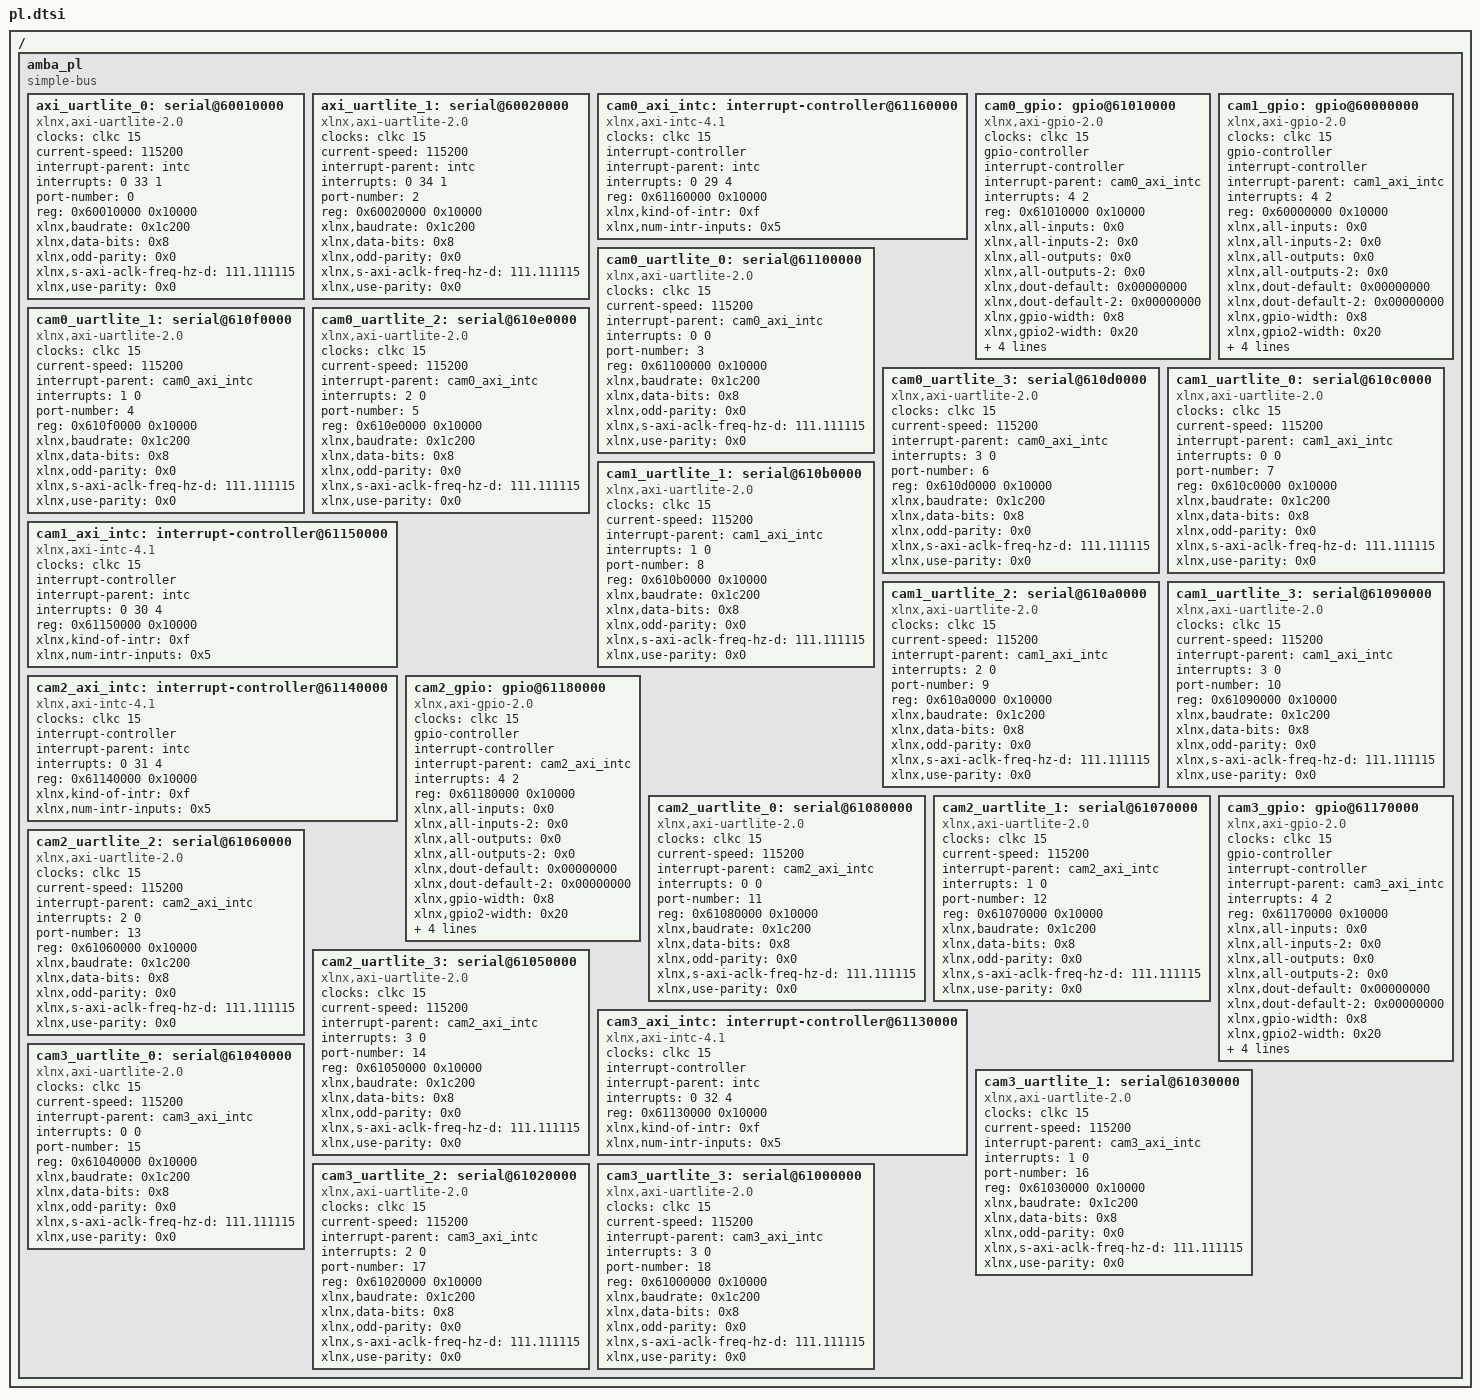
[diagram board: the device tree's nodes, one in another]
/*
 * CAUTION: This file is automatically generated by Xilinx.
 * Version:  
 * Today is: Thu Jul 18 16:22:56 2024
 */


/ {
	amba_pl: amba_pl {
		#address-cells = <1>;
		#size-cells = <1>;
		compatible = "simple-bus";
		ranges ;
		axi_uartlite_0: serial@60010000 {
			clock-names = "s_axi_aclk";
			clocks = <&clkc 15>;
			compatible = "xlnx,axi-uartlite-2.0", "xlnx,xps-uartlite-1.00.a";
			current-speed = <115200>;
			device_type = "serial";
			interrupt-names = "interrupt";
			interrupt-parent = <&intc>;
			interrupts = <0 33 1>;
			port-number = <0>;
			reg = <0x60010000 0x10000>;
			xlnx,baudrate = <0x1c200>;
			xlnx,data-bits = <0x8>;
			xlnx,odd-parity = <0x0>;
			xlnx,s-axi-aclk-freq-hz-d = "111.111115";
			xlnx,use-parity = <0x0>;
		};
		axi_uartlite_1: serial@60020000 {
			clock-names = "s_axi_aclk";
			clocks = <&clkc 15>;
			compatible = "xlnx,axi-uartlite-2.0", "xlnx,xps-uartlite-1.00.a";
			current-speed = <115200>;
			device_type = "serial";
			interrupt-names = "interrupt";
			interrupt-parent = <&intc>;
			interrupts = <0 34 1>;
			port-number = <2>;
			reg = <0x60020000 0x10000>;
			xlnx,baudrate = <0x1c200>;
			xlnx,data-bits = <0x8>;
			xlnx,odd-parity = <0x0>;
			xlnx,s-axi-aclk-freq-hz-d = "111.111115";
			xlnx,use-parity = <0x0>;
		};
		cam0_axi_intc: interrupt-controller@61160000 {
			#interrupt-cells = <2>;
			clock-names = "s_axi_aclk";
			clocks = <&clkc 15>;
			compatible = "xlnx,axi-intc-4.1", "xlnx,xps-intc-1.00.a";
			interrupt-controller ;
			interrupt-names = "irq";
			interrupt-parent = <&intc>;
			interrupts = <0 29 4>;
			reg = <0x61160000 0x10000>;
			xlnx,kind-of-intr = <0xf>;
			xlnx,num-intr-inputs = <0x5>;
		};
		cam0_gpio: gpio@61010000 {
			#gpio-cells = <2>;
			#interrupt-cells = <2>;
			clock-names = "s_axi_aclk";
			clocks = <&clkc 15>;
			compatible = "xlnx,axi-gpio-2.0", "xlnx,xps-gpio-1.00.a";
			gpio-controller ;
			interrupt-controller ;
			interrupt-names = "ip2intc_irpt";
			interrupt-parent = <&cam0_axi_intc>;
			interrupts = <4 2>;
			reg = <0x61010000 0x10000>;
			xlnx,all-inputs = <0x0>;
			xlnx,all-inputs-2 = <0x0>;
			xlnx,all-outputs = <0x0>;
			xlnx,all-outputs-2 = <0x0>;
			xlnx,dout-default = <0x00000000>;
			xlnx,dout-default-2 = <0x00000000>;
			xlnx,gpio-width = <0x8>;
			xlnx,gpio2-width = <0x20>;
			xlnx,interrupt-present = <0x1>;
			xlnx,is-dual = <0x0>;
			xlnx,tri-default = <0xFFFFFFFF>;
			xlnx,tri-default-2 = <0xFFFFFFFF>;
		};
		cam0_uartlite_0: serial@61100000 {
			clock-names = "s_axi_aclk";
			clocks = <&clkc 15>;
			compatible = "xlnx,axi-uartlite-2.0", "xlnx,xps-uartlite-1.00.a";
			current-speed = <115200>;
			device_type = "serial";
			interrupt-names = "interrupt";
			interrupt-parent = <&cam0_axi_intc>;
			interrupts = <0 0>;
			port-number = <3>;
			reg = <0x61100000 0x10000>;
			xlnx,baudrate = <0x1c200>;
			xlnx,data-bits = <0x8>;
			xlnx,odd-parity = <0x0>;
			xlnx,s-axi-aclk-freq-hz-d = "111.111115";
			xlnx,use-parity = <0x0>;
		};
		cam0_uartlite_1: serial@610f0000 {
			clock-names = "s_axi_aclk";
			clocks = <&clkc 15>;
			compatible = "xlnx,axi-uartlite-2.0", "xlnx,xps-uartlite-1.00.a";
			current-speed = <115200>;
			device_type = "serial";
			interrupt-names = "interrupt";
			interrupt-parent = <&cam0_axi_intc>;
			interrupts = <1 0>;
			port-number = <4>;
			reg = <0x610f0000 0x10000>;
			xlnx,baudrate = <0x1c200>;
			xlnx,data-bits = <0x8>;
			xlnx,odd-parity = <0x0>;
			xlnx,s-axi-aclk-freq-hz-d = "111.111115";
			xlnx,use-parity = <0x0>;
		};
		cam0_uartlite_2: serial@610e0000 {
			clock-names = "s_axi_aclk";
			clocks = <&clkc 15>;
			compatible = "xlnx,axi-uartlite-2.0", "xlnx,xps-uartlite-1.00.a";
			current-speed = <115200>;
			device_type = "serial";
			interrupt-names = "interrupt";
			interrupt-parent = <&cam0_axi_intc>;
			interrupts = <2 0>;
			port-number = <5>;
			reg = <0x610e0000 0x10000>;
			xlnx,baudrate = <0x1c200>;
			xlnx,data-bits = <0x8>;
			xlnx,odd-parity = <0x0>;
			xlnx,s-axi-aclk-freq-hz-d = "111.111115";
			xlnx,use-parity = <0x0>;
		};
		cam0_uartlite_3: serial@610d0000 {
			clock-names = "s_axi_aclk";
			clocks = <&clkc 15>;
			compatible = "xlnx,axi-uartlite-2.0", "xlnx,xps-uartlite-1.00.a";
			current-speed = <115200>;
			device_type = "serial";
			interrupt-names = "interrupt";
			interrupt-parent = <&cam0_axi_intc>;
			interrupts = <3 0>;
			port-number = <6>;
			reg = <0x610d0000 0x10000>;
			xlnx,baudrate = <0x1c200>;
			xlnx,data-bits = <0x8>;
			xlnx,odd-parity = <0x0>;
			xlnx,s-axi-aclk-freq-hz-d = "111.111115";
			xlnx,use-parity = <0x0>;
		};
		cam1_axi_intc: interrupt-controller@61150000 {
			#interrupt-cells = <2>;
			clock-names = "s_axi_aclk";
			clocks = <&clkc 15>;
			compatible = "xlnx,axi-intc-4.1", "xlnx,xps-intc-1.00.a";
			interrupt-controller ;
			interrupt-names = "irq";
			interrupt-parent = <&intc>;
			interrupts = <0 30 4>;
			reg = <0x61150000 0x10000>;
			xlnx,kind-of-intr = <0xf>;
			xlnx,num-intr-inputs = <0x5>;
		};
		cam1_gpio: gpio@60000000 {
			#gpio-cells = <2>;
			#interrupt-cells = <2>;
			clock-names = "s_axi_aclk";
			clocks = <&clkc 15>;
			compatible = "xlnx,axi-gpio-2.0", "xlnx,xps-gpio-1.00.a";
			gpio-controller ;
			interrupt-controller ;
			interrupt-names = "ip2intc_irpt";
			interrupt-parent = <&cam1_axi_intc>;
			interrupts = <4 2>;
			reg = <0x60000000 0x10000>;
			xlnx,all-inputs = <0x0>;
			xlnx,all-inputs-2 = <0x0>;
			xlnx,all-outputs = <0x0>;
			xlnx,all-outputs-2 = <0x0>;
			xlnx,dout-default = <0x00000000>;
			xlnx,dout-default-2 = <0x00000000>;
			xlnx,gpio-width = <0x8>;
			xlnx,gpio2-width = <0x20>;
			xlnx,interrupt-present = <0x1>;
			xlnx,is-dual = <0x0>;
			xlnx,tri-default = <0xFFFFFFFF>;
			xlnx,tri-default-2 = <0xFFFFFFFF>;
		};
		cam1_uartlite_0: serial@610c0000 {
			clock-names = "s_axi_aclk";
			clocks = <&clkc 15>;
			compatible = "xlnx,axi-uartlite-2.0", "xlnx,xps-uartlite-1.00.a";
			current-speed = <115200>;
			device_type = "serial";
			interrupt-names = "interrupt";
			interrupt-parent = <&cam1_axi_intc>;
			interrupts = <0 0>;
			port-number = <7>;
			reg = <0x610c0000 0x10000>;
			xlnx,baudrate = <0x1c200>;
			xlnx,data-bits = <0x8>;
			xlnx,odd-parity = <0x0>;
			xlnx,s-axi-aclk-freq-hz-d = "111.111115";
			xlnx,use-parity = <0x0>;
		};
		cam1_uartlite_1: serial@610b0000 {
			clock-names = "s_axi_aclk";
			clocks = <&clkc 15>;
			compatible = "xlnx,axi-uartlite-2.0", "xlnx,xps-uartlite-1.00.a";
			current-speed = <115200>;
			device_type = "serial";
			interrupt-names = "interrupt";
			interrupt-parent = <&cam1_axi_intc>;
			interrupts = <1 0>;
			port-number = <8>;
			reg = <0x610b0000 0x10000>;
			xlnx,baudrate = <0x1c200>;
			xlnx,data-bits = <0x8>;
			xlnx,odd-parity = <0x0>;
			xlnx,s-axi-aclk-freq-hz-d = "111.111115";
			xlnx,use-parity = <0x0>;
		};
		cam1_uartlite_2: serial@610a0000 {
			clock-names = "s_axi_aclk";
			clocks = <&clkc 15>;
			compatible = "xlnx,axi-uartlite-2.0", "xlnx,xps-uartlite-1.00.a";
			current-speed = <115200>;
			device_type = "serial";
			interrupt-names = "interrupt";
			interrupt-parent = <&cam1_axi_intc>;
			interrupts = <2 0>;
			port-number = <9>;
			reg = <0x610a0000 0x10000>;
			xlnx,baudrate = <0x1c200>;
			xlnx,data-bits = <0x8>;
			xlnx,odd-parity = <0x0>;
			xlnx,s-axi-aclk-freq-hz-d = "111.111115";
			xlnx,use-parity = <0x0>;
		};
		cam1_uartlite_3: serial@61090000 {
			clock-names = "s_axi_aclk";
			clocks = <&clkc 15>;
			compatible = "xlnx,axi-uartlite-2.0", "xlnx,xps-uartlite-1.00.a";
			current-speed = <115200>;
			device_type = "serial";
			interrupt-names = "interrupt";
			interrupt-parent = <&cam1_axi_intc>;
			interrupts = <3 0>;
			port-number = <10>;
			reg = <0x61090000 0x10000>;
			xlnx,baudrate = <0x1c200>;
			xlnx,data-bits = <0x8>;
			xlnx,odd-parity = <0x0>;
			xlnx,s-axi-aclk-freq-hz-d = "111.111115";
			xlnx,use-parity = <0x0>;
		};
		cam2_axi_intc: interrupt-controller@61140000 {
			#interrupt-cells = <2>;
			clock-names = "s_axi_aclk";
			clocks = <&clkc 15>;
			compatible = "xlnx,axi-intc-4.1", "xlnx,xps-intc-1.00.a";
			interrupt-controller ;
			interrupt-names = "irq";
			interrupt-parent = <&intc>;
			interrupts = <0 31 4>;
			reg = <0x61140000 0x10000>;
			xlnx,kind-of-intr = <0xf>;
			xlnx,num-intr-inputs = <0x5>;
		};
		cam2_gpio: gpio@61180000 {
			#gpio-cells = <2>;
			#interrupt-cells = <2>;
			clock-names = "s_axi_aclk";
			clocks = <&clkc 15>;
			compatible = "xlnx,axi-gpio-2.0", "xlnx,xps-gpio-1.00.a";
			gpio-controller ;
			interrupt-controller ;
			interrupt-names = "ip2intc_irpt";
			interrupt-parent = <&cam2_axi_intc>;
			interrupts = <4 2>;
			reg = <0x61180000 0x10000>;
			xlnx,all-inputs = <0x0>;
			xlnx,all-inputs-2 = <0x0>;
			xlnx,all-outputs = <0x0>;
			xlnx,all-outputs-2 = <0x0>;
			xlnx,dout-default = <0x00000000>;
			xlnx,dout-default-2 = <0x00000000>;
			xlnx,gpio-width = <0x8>;
			xlnx,gpio2-width = <0x20>;
			xlnx,interrupt-present = <0x1>;
			xlnx,is-dual = <0x0>;
			xlnx,tri-default = <0xFFFFFFFF>;
			xlnx,tri-default-2 = <0xFFFFFFFF>;
		};
		cam2_uartlite_0: serial@61080000 {
			clock-names = "s_axi_aclk";
			clocks = <&clkc 15>;
			compatible = "xlnx,axi-uartlite-2.0", "xlnx,xps-uartlite-1.00.a";
			current-speed = <115200>;
			device_type = "serial";
			interrupt-names = "interrupt";
			interrupt-parent = <&cam2_axi_intc>;
			interrupts = <0 0>;
			port-number = <11>;
			reg = <0x61080000 0x10000>;
			xlnx,baudrate = <0x1c200>;
			xlnx,data-bits = <0x8>;
			xlnx,odd-parity = <0x0>;
			xlnx,s-axi-aclk-freq-hz-d = "111.111115";
			xlnx,use-parity = <0x0>;
		};
		cam2_uartlite_1: serial@61070000 {
			clock-names = "s_axi_aclk";
			clocks = <&clkc 15>;
			compatible = "xlnx,axi-uartlite-2.0", "xlnx,xps-uartlite-1.00.a";
			current-speed = <115200>;
			device_type = "serial";
			interrupt-names = "interrupt";
			interrupt-parent = <&cam2_axi_intc>;
			interrupts = <1 0>;
			port-number = <12>;
			reg = <0x61070000 0x10000>;
			xlnx,baudrate = <0x1c200>;
			xlnx,data-bits = <0x8>;
			xlnx,odd-parity = <0x0>;
			xlnx,s-axi-aclk-freq-hz-d = "111.111115";
			xlnx,use-parity = <0x0>;
		};
		cam2_uartlite_2: serial@61060000 {
			clock-names = "s_axi_aclk";
			clocks = <&clkc 15>;
			compatible = "xlnx,axi-uartlite-2.0", "xlnx,xps-uartlite-1.00.a";
			current-speed = <115200>;
			device_type = "serial";
			interrupt-names = "interrupt";
			interrupt-parent = <&cam2_axi_intc>;
			interrupts = <2 0>;
			port-number = <13>;
			reg = <0x61060000 0x10000>;
			xlnx,baudrate = <0x1c200>;
			xlnx,data-bits = <0x8>;
			xlnx,odd-parity = <0x0>;
			xlnx,s-axi-aclk-freq-hz-d = "111.111115";
			xlnx,use-parity = <0x0>;
		};
		cam2_uartlite_3: serial@61050000 {
			clock-names = "s_axi_aclk";
			clocks = <&clkc 15>;
			compatible = "xlnx,axi-uartlite-2.0", "xlnx,xps-uartlite-1.00.a";
			current-speed = <115200>;
			device_type = "serial";
			interrupt-names = "interrupt";
			interrupt-parent = <&cam2_axi_intc>;
			interrupts = <3 0>;
			port-number = <14>;
			reg = <0x61050000 0x10000>;
			xlnx,baudrate = <0x1c200>;
			xlnx,data-bits = <0x8>;
			xlnx,odd-parity = <0x0>;
			xlnx,s-axi-aclk-freq-hz-d = "111.111115";
			xlnx,use-parity = <0x0>;
		};
		cam3_axi_intc: interrupt-controller@61130000 {
			#interrupt-cells = <2>;
			clock-names = "s_axi_aclk";
			clocks = <&clkc 15>;
			compatible = "xlnx,axi-intc-4.1", "xlnx,xps-intc-1.00.a";
			interrupt-controller ;
			interrupt-names = "irq";
			interrupt-parent = <&intc>;
			interrupts = <0 32 4>;
			reg = <0x61130000 0x10000>;
			xlnx,kind-of-intr = <0xf>;
			xlnx,num-intr-inputs = <0x5>;
		};
		cam3_gpio: gpio@61170000 {
			#gpio-cells = <2>;
			#interrupt-cells = <2>;
			clock-names = "s_axi_aclk";
			clocks = <&clkc 15>;
			compatible = "xlnx,axi-gpio-2.0", "xlnx,xps-gpio-1.00.a";
			gpio-controller ;
			interrupt-controller ;
			interrupt-names = "ip2intc_irpt";
			interrupt-parent = <&cam3_axi_intc>;
			interrupts = <4 2>;
			reg = <0x61170000 0x10000>;
			xlnx,all-inputs = <0x0>;
			xlnx,all-inputs-2 = <0x0>;
			xlnx,all-outputs = <0x0>;
			xlnx,all-outputs-2 = <0x0>;
			xlnx,dout-default = <0x00000000>;
			xlnx,dout-default-2 = <0x00000000>;
			xlnx,gpio-width = <0x8>;
			xlnx,gpio2-width = <0x20>;
			xlnx,interrupt-present = <0x1>;
			xlnx,is-dual = <0x0>;
			xlnx,tri-default = <0xFFFFFFFF>;
			xlnx,tri-default-2 = <0xFFFFFFFF>;
		};
		cam3_uartlite_0: serial@61040000 {
			clock-names = "s_axi_aclk";
			clocks = <&clkc 15>;
			compatible = "xlnx,axi-uartlite-2.0", "xlnx,xps-uartlite-1.00.a";
			current-speed = <115200>;
			device_type = "serial";
			interrupt-names = "interrupt";
			interrupt-parent = <&cam3_axi_intc>;
			interrupts = <0 0>;
			port-number = <15>;
			reg = <0x61040000 0x10000>;
			xlnx,baudrate = <0x1c200>;
			xlnx,data-bits = <0x8>;
			xlnx,odd-parity = <0x0>;
			xlnx,s-axi-aclk-freq-hz-d = "111.111115";
			xlnx,use-parity = <0x0>;
		};
		cam3_uartlite_1: serial@61030000 {
			clock-names = "s_axi_aclk";
			clocks = <&clkc 15>;
			compatible = "xlnx,axi-uartlite-2.0", "xlnx,xps-uartlite-1.00.a";
			current-speed = <115200>;
			device_type = "serial";
			interrupt-names = "interrupt";
			interrupt-parent = <&cam3_axi_intc>;
			interrupts = <1 0>;
			port-number = <16>;
			reg = <0x61030000 0x10000>;
			xlnx,baudrate = <0x1c200>;
			xlnx,data-bits = <0x8>;
			xlnx,odd-parity = <0x0>;
			xlnx,s-axi-aclk-freq-hz-d = "111.111115";
			xlnx,use-parity = <0x0>;
		};
		cam3_uartlite_2: serial@61020000 {
			clock-names = "s_axi_aclk";
			clocks = <&clkc 15>;
			compatible = "xlnx,axi-uartlite-2.0", "xlnx,xps-uartlite-1.00.a";
			current-speed = <115200>;
			device_type = "serial";
			interrupt-names = "interrupt";
			interrupt-parent = <&cam3_axi_intc>;
			interrupts = <2 0>;
			port-number = <17>;
			reg = <0x61020000 0x10000>;
			xlnx,baudrate = <0x1c200>;
			xlnx,data-bits = <0x8>;
			xlnx,odd-parity = <0x0>;
			xlnx,s-axi-aclk-freq-hz-d = "111.111115";
			xlnx,use-parity = <0x0>;
		};
		cam3_uartlite_3: serial@61000000 {
			clock-names = "s_axi_aclk";
			clocks = <&clkc 15>;
			compatible = "xlnx,axi-uartlite-2.0", "xlnx,xps-uartlite-1.00.a";
			current-speed = <115200>;
			device_type = "serial";
			interrupt-names = "interrupt";
			interrupt-parent = <&cam3_axi_intc>;
			interrupts = <3 0>;
			port-number = <18>;
			reg = <0x61000000 0x10000>;
			xlnx,baudrate = <0x1c200>;
			xlnx,data-bits = <0x8>;
			xlnx,odd-parity = <0x0>;
			xlnx,s-axi-aclk-freq-hz-d = "111.111115";
			xlnx,use-parity = <0x0>;
		};
	};
};
